AUTOSAR XML (schema 3.1.2)
package /Components/SWC_DfwCtl
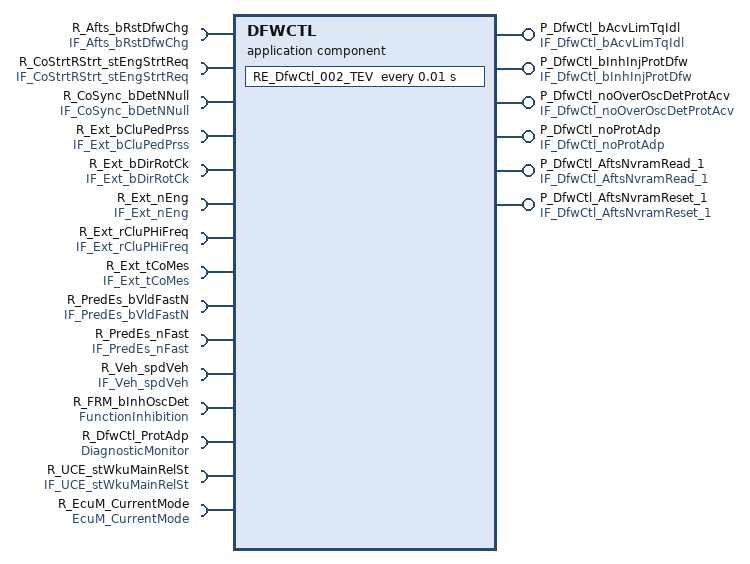
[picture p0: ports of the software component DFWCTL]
  application software component type DFWCTL
    12 x require port:
      R_Afts_bRstDfwChg: unqueued-receiver-com-spec{data-element=Afts_bRstDfwChg, init-value=Afts_bRstDfwChg_in, resync-time=0}, required-interface=IF_Afts_bRstDfwChg
      R_CoStrtRStrt_stEngStrtReq: unqueued-receiver-com-spec{data-element=CoStrtRStrt_stEngStrtReq, init-value=CoStrtRStrt_stEngStrtReq_in, resync-time=0}, required-interface=IF_CoStrtRStrt_stEngStrtReq
      R_CoSync_bDetNNull: unqueued-receiver-com-spec{data-element=CoSync_bDetNNull, init-value=ConstantValue, resync-time=0}, required-interface=IF_CoSync_bDetNNull
      R_Ext_bCluPedPrss: unqueued-receiver-com-spec{data-element=Ext_bCluPedPrss, init-value=ConstantValue1, resync-time=0}, required-interface=IF_Ext_bCluPedPrss
      R_Ext_bDirRotCk: unqueued-receiver-com-spec{data-element=Ext_bDirRotCk, init-value=Ext_bDirRotCk_in, resync-time=0}, required-interface=IF_Ext_bDirRotCk
      R_Ext_nEng: unqueued-receiver-com-spec{data-element=Ext_nEng, init-value=ConstantValue3, resync-time=0}, required-interface=IF_Ext_nEng
      R_Ext_rCluPHiFreq: unqueued-receiver-com-spec{data-element=Ext_rCluPHiFreq, init-value=ConstantValue5, resync-time=0}, required-interface=IF_Ext_rCluPHiFreq
      R_Ext_tCoMes: unqueued-receiver-com-spec{data-element=Ext_tCoMes, init-value=ConstantValue7, resync-time=0}, required-interface=IF_Ext_tCoMes
      R_PredEs_bVldFastN: unqueued-receiver-com-spec{data-element=PredEs_bVldFastN, init-value=PredEs_bVldFastN_in, resync-time=0}, required-interface=IF_PredEs_bVldFastN
      R_PredEs_nFast: unqueued-receiver-com-spec{data-element=PredEs_nFast, init-value=ConstantValue9, resync-time=0}, required-interface=IF_PredEs_nFast
      R_Veh_spdVeh: unqueued-receiver-com-spec{data-element=Veh_spdVeh, init-value=ConstantValue11, resync-time=0}, required-interface=IF_Veh_spdVeh
      R_FRM_bInhOscDet: required-interface=FunctionInhibition
    4 x provide port:
      P_DfwCtl_bAcvLimTqIdl: unqueued-sender-com-spec{data-element=DfwCtl_bAcvLimTqIdl, can-invalidate=false, init-value=ConstantValue13}, provided-interface=IF_DfwCtl_bAcvLimTqIdl
      P_DfwCtl_bInhInjProtDfw: unqueued-sender-com-spec{data-element=DfwCtl_bInhInjProtDfw, can-invalidate=false, init-value=DfwCtl_bInhInjProtDfw_out}, provided-interface=IF_DfwCtl_bInhInjProtDfw
      P_DfwCtl_noOverOscDetProtAcv: unqueued-sender-com-spec{data-element=DfwCtl_noOverOscDetProtAcv, can-invalidate=false, init-value=DfwCtl_noOverOscDetProtAcv_out}, provided-interface=IF_DfwCtl_noOverOscDetProtAcv
      P_DfwCtl_noProtAdp: unqueued-sender-com-spec{data-element=DfwCtl_noProtAdp, can-invalidate=false, init-value=DfwCtl_noProtAdp_out}, provided-interface=IF_DfwCtl_noProtAdp
    require port R_DfwCtl_ProtAdp: required-interface=DiagnosticMonitor
    require port R_UCE_stWkuMainRelSt: required-interface=IF_UCE_stWkuMainRelSt
    require port R_EcuM_CurrentMode: required-interface=EcuM_CurrentMode
    provide port P_DfwCtl_AftsNvramRead_1: server-com-spec{operation=DfwCtl_AftsNvramRead_1, queue-length=4}, provided-interface=IF_DfwCtl_AftsNvramRead_1
    provide port P_DfwCtl_AftsNvramReset_1: server-com-spec{operation=DfwCtl_AftsNvramReset_1, queue-length=4}, provided-interface=IF_DfwCtl_AftsNvramReset_1
  15 x constant specification:
    Afts_bRstDfwChg_in
      value:
        boolean literal Afts_bRstDfwChg_in: type=DT_Afts_bRstDfwChg, value=false
    ConstantValue
      value:
        boolean literal ConstantValue: type=DT_CoSync_bDetNNull, value=false
    ConstantValue1
      value:
        boolean literal ConstantValue1: type=DT_Ext_bCluPedPrss, value=false
    ConstantValue11
      value:
        integer literal ConstantValue11: type=DT_Veh_spdVeh, value=0
    ConstantValue13
      value:
        boolean literal ConstantValue13: type=DT_DfwCtl_bAcvLimTqIdl, value=false
    ConstantValue3
      value:
        integer literal ConstantValue3: type=DT_Ext_nEng, value=0
    ConstantValue5
      value:
        integer literal ConstantValue5: type=DT_Ext_rCluPHiFreq, value=0
    ConstantValue7
      value:
        integer literal ConstantValue7: type=DT_Ext_tCoMes, value=20
    ConstantValue9
      value:
        integer literal ConstantValue9: type=DT_PredEs_nFast, value=0
    CoStrtRStrt_stEngStrtReq_in
      value:
        integer literal CoStrtRStrt_stEngStrtReq_in: type=DT_CoStrtRStrt_stEngStrtReq, value=0
    DfwCtl_bInhInjProtDfw_out
      value:
        boolean literal DfwCtl_bInhInjProtDfw_out: type=DT_DfwCtl_bInhInjProtDfw, value=false
    DfwCtl_noOverOscDetProtAcv_out
      value:
        integer literal DfwCtl_noOverOscDetProtAcv_out: type=DT_DfwCtl_noOverOscDetProtAcv, value=0
    DfwCtl_noProtAdp_out
      value:
        integer literal DfwCtl_noProtAdp_out: type=DT_DfwCtl_noProtAdp, value=0
    Ext_bDirRotCk_in
      value:
        boolean literal Ext_bDirRotCk_in: type=DT_Ext_bDirRotCk, value=false
    PredEs_bVldFastN_in
      value:
        boolean literal PredEs_bVldFastN_in: type=DT_PredEs_bVldFastN, value=false
  internal behavior IB_DfwCtl: component=DFWCTL
    mode switch event EV_DfwCtl_001_MSE: start-on-event=RE_DfwCtl_001_MSE, activation=ENTRY, mode=R_EcuM_CurrentMode.currentMode.RUN
    timing event EV_DfwCtl_002_TEV: mode-dependency=dependent-on-mode=[R_UCE_stWkuMainRelSt.RCD_stWkuMainRelSt.PreMainWakeUp, R_UCE_stWkuMainRelSt.RCD_stWkuMainRelSt.PostMainWakeUp, R_UCE_stWkuMainRelSt.RCD_stWkuMainRelSt.Invalid], start-on-event=RE_DfwCtl_002_TEV, period=0.01
    operation invoked event EV_DfwCtl_AftsNvramReset_1: start-on-event=DfwCtl_AftsNvramReset_1, operation=P_DfwCtl_AftsNvramReset_1.DfwCtl_AftsNvramReset_1
    operation invoked event EV_DfwCtl_AftsNvramRead_1: start-on-event=DfwCtl_AftsNvramRead_1, operation=P_DfwCtl_AftsNvramRead_1.DfwCtl_AftsNvramRead_1
    4 x runnable:
      RE_DfwCtl_002_TEV
        11 x data receive point:
          dr_CoSync_bDetNNull: data-element=R_CoSync_bDetNNull.CoSync_bDetNNull
          dr_Ext_tCoMes: data-element=R_Ext_tCoMes.Ext_tCoMes
          dr_Veh_spdVeh: data-element=R_Veh_spdVeh.Veh_spdVeh
          dr_Ext_nEng: data-element=R_Ext_nEng.Ext_nEng
          dr_PredEs_bVldFastN: data-element=R_PredEs_bVldFastN.PredEs_bVldFastN
          dr_Ext_bDirRotCk: data-element=R_Ext_bDirRotCk.Ext_bDirRotCk
          dr_Ext_bCluPedPrss: data-element=R_Ext_bCluPedPrss.Ext_bCluPedPrss
          dr_PredEs_nFast: data-element=R_PredEs_nFast.PredEs_nFast
          dr_Ext_rCluPHiFreq: data-element=R_Ext_rCluPHiFreq.Ext_rCluPHiFreq
          dr_CoStrtRStrt_stEngStrtReq: data-element=R_CoStrtRStrt_stEngStrtReq.CoStrtRStrt_stEngStrtReq
          dr_Afts_bRstDfwChg: data-element=R_Afts_bRstDfwChg.Afts_bRstDfwChg
        4 x data send point:
          ds_DfwCtl_noOverOscDetProtAcv: data-element=P_DfwCtl_noOverOscDetProtAcv.DfwCtl_noOverOscDetProtAcv
          ds_DfwCtl_bAcvLimTqIdl: data-element=P_DfwCtl_bAcvLimTqIdl.DfwCtl_bAcvLimTqIdl
          ds_DfwCtl_noProtAdp: data-element=P_DfwCtl_noProtAdp.DfwCtl_noProtAdp
          ds_DfwCtl_bInhInjProtDfw: data-element=P_DfwCtl_bInhInjProtDfw.DfwCtl_bInhInjProtDfw
        sync call ssp_DfwCtl_ProtAdp: operation=R_DfwCtl_ProtAdp.SetEventStatus
        sync call ssp_FRM_bInhOscDet: operation=R_FRM_bInhOscDet.GetFunctionPermission
      RE_DfwCtl_001_MSE
        4 x data send point:
          ds_DfwCtl_bAcvLimTqIdl: data-element=P_DfwCtl_bAcvLimTqIdl.DfwCtl_bAcvLimTqIdl
          ds_DfwCtl_noProtAdp: data-element=P_DfwCtl_noProtAdp.DfwCtl_noProtAdp
          ds_DfwCtl_bInhInjProtDfw: data-element=P_DfwCtl_bInhInjProtDfw.DfwCtl_bInhInjProtDfw
          ds_DfwCtl_noOverOscDetProtAcv: data-element=P_DfwCtl_noOverOscDetProtAcv.DfwCtl_noOverOscDetProtAcv
      DfwCtl_AftsNvramRead_1
      DfwCtl_AftsNvramReset_1
  swc implementation Imp_DfwCtl: programming-language=C, behavior=IB_DfwCtl
    code-descriptors:
      code CodeDescriptor: type=SRC
        10 x xfile:
          DfwCtl_nvm_c: url=DfwCtl_nvm.c
          DfwCtl_nvm_h: url=DfwCtl_nvm.h
          DfwCtl_afts_c: url=DfwCtl_afts.c
          DfwCtl_c: url=DfwCtl.c
          DfwCtl_002_TEV_fct_c: url=DfwCtl_002_TEV_fct.c
          DfwCtl_calibrations_h: url=DfwCtl_calibrations.h
          DfwCtl_002_TEV_fct_h: url=DfwCtl_002_TEV_fct.h
          DfwCtl_h: url=DfwCtl.h
          DfwCtl_calibrations_c: url=DfwCtl_calibrations.c
          DfwCtl_MemMap_h: url=DfwCtl_MemMap.h
